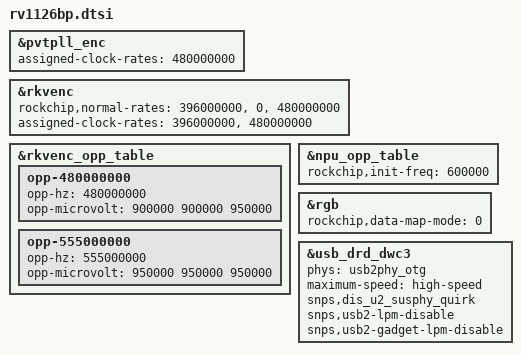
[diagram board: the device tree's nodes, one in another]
// SPDX-License-Identifier: (GPL-2.0+ OR MIT)
/*
 * Copyright (c) 2025 Rockchip Electronics Co., Ltd.
 */

#include "rv1126b.dtsi"

/ {
};

&pvtpll_enc {
	assigned-clock-rates = <480000000>;
};

&rkvenc {
	rockchip,normal-rates = <396000000>, <0>, <480000000>;
	assigned-clock-rates = <396000000>, <480000000>;
};

&rkvenc_opp_table {
	/delete-node/ opp-550000000;
	opp-480000000 {
		opp-hz = /bits/ 64 <480000000>;
		opp-microvolt = <900000 900000 950000>;
	};
	opp-555000000 {
		opp-hz = /bits/ 64 <555000000>;
		opp-microvolt = <950000 950000 950000>;
	};
};

&npu_opp_table {
	rockchip,init-freq = <600000>;
};

&rgb {
	/*
	 * RV1126 compatible pin output mode 0.
	 *
	 * MCU: ROCKCHIP_MCU_DATA_MAP_DATA_1x24
	 * BT1120: ROCKCHIP_BT1120_DATA_MAP_DATA_PADLO
	 * BT656: ROCKCHIP_BT656_DATA_MAP_PADLO
	 */
	rockchip,data-map-mode = <0>;
};

&usb_drd_dwc3 {
	phys = <&usb2phy_otg>;
	phy-names = "usb2-phy";
	maximum-speed = "high-speed";
	snps,dis_u2_susphy_quirk;
	snps,usb2-lpm-disable;
	snps,usb2-gadget-lpm-disable;
};
